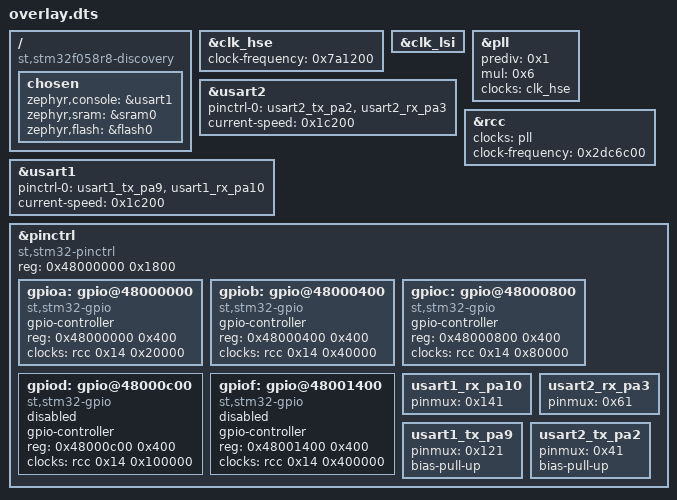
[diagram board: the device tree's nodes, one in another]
/ {
	compatible = "st,stm32f058r8-discovery";
	chosen {
		zephyr,console = &usart1;
		zephyr,sram = &sram0;
		zephyr,flash = &flash0;
	};
};
&clk_hse{
	status = "okay";
	clock-frequency = < 0x7a1200 >;
};
&clk_lsi{
	status = "okay";
};
&pll{
	status = "okay";
	prediv = < 0x1 >;
	mul = < 0x6 >;
	clocks = < &clk_hse >;
};
&usart2{
	status = "okay";
	pinctrl-0 = < &usart2_tx_pa2 &usart2_rx_pa3 >;
	pinctrl-names = "default";
	current-speed = < 0x1c200 >;
};
&rcc{
	clocks = < &pll >;
	clock-frequency = < 0x2dc6c00 >;
};
&usart1{
	status = "okay";
	pinctrl-0 = < &usart1_tx_pa9 &usart1_rx_pa10 >;
	pinctrl-names = "default";
	current-speed = < 0x1c200 >;
};
&pinctrl{
	compatible = "st,stm32-pinctrl";
	#address-cells = < 0x1 >;
	#size-cells = < 0x1 >;
	reg = < 0x48000000 0x1800 >;
	gpioa: gpio@48000000 {
		compatible = "st,stm32-gpio";
		gpio-controller;
		#gpio-cells = < 0x2 >;
		reg = < 0x48000000 0x400 >;
		clocks = < &rcc 0x14 0x20000 >;
	};
	gpiob: gpio@48000400 {
		compatible = "st,stm32-gpio";
		gpio-controller;
		#gpio-cells = < 0x2 >;
		reg = < 0x48000400 0x400 >;
		clocks = < &rcc 0x14 0x40000 >;
	};
	gpioc: gpio@48000800 {
		compatible = "st,stm32-gpio";
		gpio-controller;
		#gpio-cells = < 0x2 >;
		reg = < 0x48000800 0x400 >;
		clocks = < &rcc 0x14 0x80000 >;
	};
	gpiod: gpio@48000c00 {
		compatible = "st,stm32-gpio";
		gpio-controller;
		#gpio-cells = < 0x2 >;
		reg = < 0x48000c00 0x400 >;
		clocks = < &rcc 0x14 0x100000 >;
		status = "disabled";
	};
	gpiof: gpio@48001400 {
		compatible = "st,stm32-gpio";
		gpio-controller;
		#gpio-cells = < 0x2 >;
		reg = < 0x48001400 0x400 >;
		clocks = < &rcc 0x14 0x400000 >;
		status = "disabled";
	};
	usart1_rx_pa10: usart1_rx_pa10 {
		pinmux = < 0x141 >;
	};
	usart2_rx_pa3: usart2_rx_pa3 {
		pinmux = < 0x61 >;
	};
	usart1_tx_pa9: usart1_tx_pa9 {
		pinmux = < 0x121 >;
		bias-pull-up;
	};
	usart2_tx_pa2: usart2_tx_pa2 {
		pinmux = < 0x41 >;
		bias-pull-up;
	};
};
